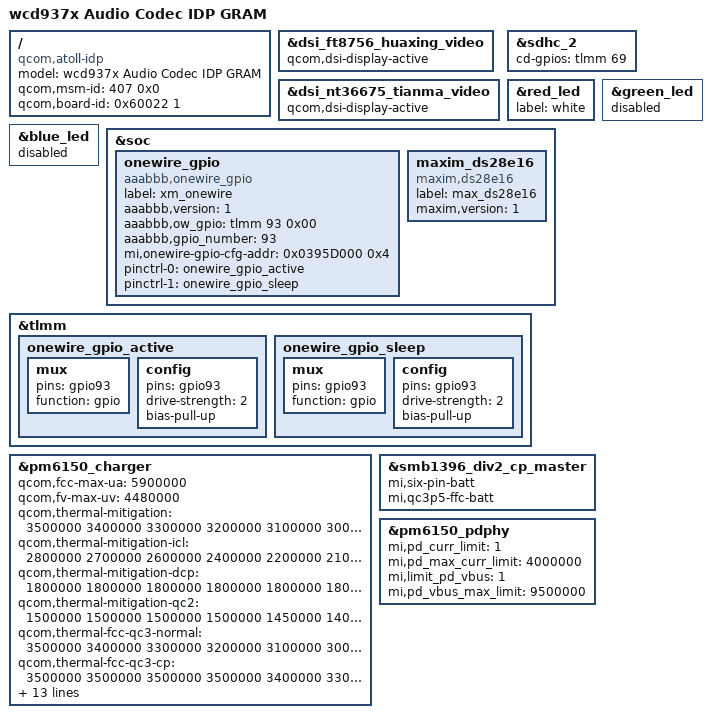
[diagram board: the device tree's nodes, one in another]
/* Copyright (c) 2019, The Linux Foundation. All rights reserved.
 * Copyright (C) 2020 XiaoMi, Inc.
 *
 * This program is free software; you can redistribute it and/or modify
 * it under the terms of the GNU General Public License version 2 and
 * only version 2 as published by the Free Software Foundation.
 *
 * This program is distributed in the hope that it will be useful,
 * but WITHOUT ANY WARRANTY; without even the implied warranty of
 * MERCHANTABILITY or FITNESS FOR A PARTICULAR PURPOSE.  See the
 * GNU General Public License for more details.
 */

/dts-v1/;
/plugin/;

#include <dt-bindings/interrupt-controller/arm-gic.h>

#include "cust-atoll.dtsi"
#include "atoll-idp.dtsi"
#include "cust-msm-audio-lpass.dtsi"
#include "cust-atoll-pinctrl-overlay.dtsi"
#include "cust-atoll-regulator.dtsi"
#include "cust-atoll-sde-display.dtsi"
#include "cust-atoll-thermal.dtsi"
#include "cust-atoll-usb.dtsi"
#include "cust-atoll-idp.dtsi"
#include "atoll-wcd937x-idp-audio-overlay.dtsi"
#include "cust-atoll-audio-overlay.dtsi"
#include "custg-atoll-camera-sensor-idp.dtsi"

/ {
	model = "wcd937x Audio Codec IDP GRAM";
	compatible = "qcom,atoll-idp", "qcom,atoll", "qcom,idp";
	qcom,msm-id = <407 0x0>;
	qcom,board-id = <0x60022 1>;
};

&dsi_ft8756_huaxing_video {
	qcom,dsi-display-active;
};
&dsi_nt36675_tianma_video {
	qcom,dsi-display-active;
};
&sdhc_2 {
	cd-gpios = <&tlmm 69 0>;
};

&red_led {
	label = "white";
};

&green_led {
	status = "disabled";
};

&blue_led {
	status = "disabled";
};

&soc {
	onewire_gpio: onewire_gpio {
		compatible = "aaabbb,onewire_gpio";
		label = "xm_onewire";
		aaabbb,version = <1>;
		aaabbb,ow_gpio = <&tlmm 93 0x00>;
		aaabbb,gpio_number = <93>;
		mi,onewire-gpio-cfg-addr = <0x0395D000 0x4>;
		pinctrl-names = "onewire_active", "onewire_sleep";
		pinctrl-0 = <&onewire_gpio_active>;
		pinctrl-1 = <&onewire_gpio_sleep>;
		status = "ok";
	};

	maxim_ds28e16: maxim_ds28e16 {
		compatible = "maxim,ds28e16";
		label = "max_ds28e16";
		maxim,version = <1>;
		status = "ok";
	};
};

&tlmm {
	onewire_gpio_active: onewire_gpio_active {
		mux {
			pins = "gpio93";
			function = "gpio";
		};

		config {
			pins = "gpio93";
			drive-strength = <2>;
			bias-pull-up; /* No PULL */
		};
	};

	onewire_gpio_sleep: onewire_gpio_sleep {
		mux {
			pins = "gpio93";
			function = "gpio";
		};

		config {
			pins = "gpio93";
			drive-strength = <2>;
			bias-pull-up;
		};
	};
};

&pm6150_charger {
	qcom,fcc-max-ua = <5900000>;
	qcom,fv-max-uv = <4480000>;
	qcom,thermal-mitigation = <3500000 3400000 3300000 3200000 3100000 3000000 2900000
	                           2800000 2600000 2400000 2200000 2000000 1800000 1500000
	                           1000000 500000>;
	qcom,thermal-mitigation-icl
	                        = <2800000 2700000 2600000 2400000 2200000 2100000 2000000
	                           2000000 2000000 1900000 1800000 1600000 1500000 1300000
	                           800000 750000>;
	qcom,thermal-mitigation-dcp
	                        = <1800000 1800000 1800000 1800000 1800000 1800000 1800000
	                           1800000 1800000 1700000 1600000 1400000 1200000 1100000
	                           1100000 1000000>;
	qcom,thermal-mitigation-qc2
	                        = <1500000 1500000 1500000 1500000 1450000 1400000 1350000
	                           1300000 1150000 1100000 1000000 900000 850000 750000
	                           650000 500000>;
	qcom,thermal-fcc-qc3-normal
	                        = <3500000 3400000 3300000 3200000 3100000 3000000 2900000
	                           2800000 2700000 2600000 2400000 2200000 2000000 2000000
	                           750000 700000>;
	qcom,thermal-fcc-qc3-cp
	                        = <3500000 3500000 3500000 3500000 3400000 3300000 3200000
	                           3100000 3000000 2800000 2600000 2400000 2200000 2000000
	                           1000000 700000>;
	qcom,thermal-fcc-qc3-classb-cp
	                        = <6000000 5500000 4900000 4600000 4500000 4400000 4200000
	                           3800000 3800000 3600000 3400000 3200000 3000000 2200000
	                           800000 700000>;
	qcom,thermal-fcc-qc3p5-cp
	                        = <4500000 4500000 4500000 4500000 4500000 4400000 4200000
	                           3800000 3800000 3600000 3400000 3200000 3000000 2200000
	                           800000 700000>;
	qcom,thermal-mitigation-pd-base
	                        = <2800000 2700000 2600000 2400000 2200000 2100000 2000000
	                           2000000 2000000 1900000 1800000 1600000 1500000 1300000
	                           800000 750000>;
	qcom,thermal-fcc-pps-cp
	                        = <6000000 5500000 4900000 4600000 4500000 4400000 4200000
	                           3800000 3800000 3600000 3400000 3200000 3000000 2200000
	                           800000 700000>;
	mi,six-pin-step-chg-params = <4240000  5900000
	                              4440000  4800000
	                              4480000  3800000>;
	mi,six-pin-step-chg;
	mi,support-ffc;
	qcom,temp-27W-enable;
};

&smb1396_div2_cp_master {
	mi,six-pin-batt;
	mi,qc3p5-ffc-batt;
};

&pm6150_pdphy {
	mi,pd_curr_limit = <1>;
	mi,pd_max_curr_limit = <4000000>;
	mi,limit_pd_vbus = <1>;
	mi,pd_vbus_max_limit = <9500000>;
};
